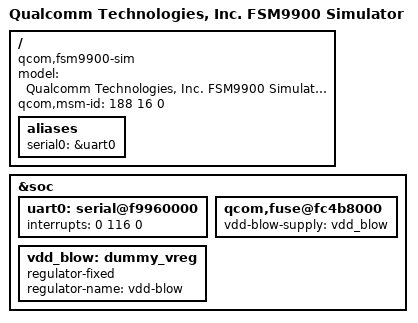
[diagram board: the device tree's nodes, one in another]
/* Copyright (c) 2013-2014, The Linux Foundation. All rights reserved.
 *
 * This program is free software; you can redistribute it and/or modify
 * it under the terms of the GNU General Public License version 2 and
 * only version 2 as published by the Free Software Foundation.
 *
 * This program is distributed in the hope that it will be useful,
 * but WITHOUT ANY WARRANTY; without even the implied warranty of
 * MERCHANTABILITY or FITNESS FOR A PARTICULAR PURPOSE.  See the
 * GNU General Public License for more details.
 */

/dts-v1/;

#include "fsm9900.dtsi"

/ {
	model = "Qualcomm Technologies, Inc. FSM9900 Simulator";
	compatible = "qcom,fsm9900-sim", "qcom,fsm9900", "qcom,sim";
	qcom,msm-id = <188 16 0>;

	aliases {
		serial0 = &uart0;
	};
};

&soc {
	uart0: serial@f9960000 {
		interrupts = <0 116 0>;
		status = "ok";
	};

	qcom,fuse@fc4b8000 {
		vdd-blow-supply = <&vdd_blow>;
		status = "ok";
	};

	vdd_blow: dummy_vreg {
		compatible = "regulator-fixed";
		status = "ok";
		regulator-name = "vdd-blow";
	};
};
